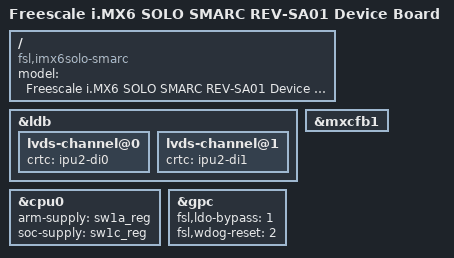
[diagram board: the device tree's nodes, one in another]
/dts-v1/;

#include "imx6dl.dtsi"
#include "imx6qdl-smarc.dtsi"
#include "imx6qdl-rev-sa01-pfuze100.dtsi"

/ {
	model = "Freescale i.MX6 SOLO SMARC REV-SA01 Device Board";
	compatible = "fsl,imx6solo-smarc", "fsl,imx6q";
};

&ldb {
	lvds-channel@0 {
		crtc = "ipu2-di0";
	};

	lvds-channel@1 {
		crtc = "ipu2-di1";
	};
};

&mxcfb1 {
	status = "okay";
};

&cpu0 {
	arm-supply = <&sw1a_reg>;
	soc-supply = <&sw1c_reg>;
};

&gpc {
	/* use ldo-bypass, u-boot will check it and configure */
	fsl,ldo-bypass = <1>;
	fsl,wdog-reset = <2>;
};
